# RK3399-AP register map
File version: 1
CPU: CA7 r0p1, little endian, MPU, FPU, I-cache, D-cache, VTOR, 4 interrupt priority bits, 0 interrupts
Registers are 32-bit, read-write, reset 0x0 unless marked. A register's access mark holds for its fields unless they carry their own. Offsets are from the block's base; [hi:lo] are bit positions; {n}, {i} and the like mark numbered series.

## PCIE
Base 0xF8000000
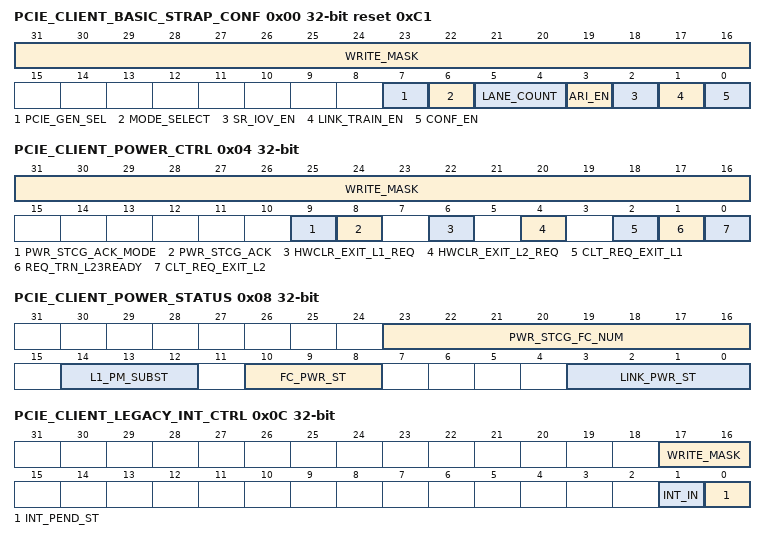
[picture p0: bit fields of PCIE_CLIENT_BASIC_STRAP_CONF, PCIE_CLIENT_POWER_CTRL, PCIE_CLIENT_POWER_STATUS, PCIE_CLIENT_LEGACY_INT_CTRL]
0x00 PCIE_CLIENT_BASIC_STRAP_CONF access per field reset 0xC1 — Basic strap configuration register
  [31:16] WRITE_MASK wo — Write mask bits For each served bit 1\'b0: write mask 1\'b1: write enable
  [7] PCIE_GEN_SEL rw — Generation support select 1\'b0: Gen1 mode 1\'b1: Gen2 mode This strap input selects the generation of the PCI Express protocol supported by the core. If Gen1 mode. The core advertises only Gen1 capability in this mode, and will always operate at Gen1 speed. If Gen2 mode. The core advertises Gen1 and Gen2 capabilities in this mode, but not Gen3. The link may operate at Gen1 or Gen2 speed.
  [6] MODE_SELECT rw — Controller operation mode select 1\'b0: Endpoint operation 1\'b1: Root Port operation
  [5:4] LANE_COUNT rw — lane count in configure the lane count supported 2’b11: reserved 2’b10: X4 2’b01: X2 2’b00: X1
  [3] ARI_EN rw — Alternate interpretation enable 1\'b0: legacy interpretation of the PCI Routing ID 1\'b1: alternate interpretation of the PCI Routing ID This input is strapped to 0 for legacy interpretation of the PCI Routing ID (8-bit Bus + 5-bit Device + 3- bit Function). A 1 at this input enables the alternate interpretation (8-bit Bus + 8-bit Function).
  [2] SR_IOV_EN rw — Single root I/O virtualization feature enable 1\'b0: disable SR-IOV feature 1\'b1: enable SR-IOV feature In a core supporting the Single Root I/O Virtualization feature, this strap input must be tied high to enable the SR-IOV feature. The ari_en input must also be strapped high to enable the SR- IOV feature.
  [1] LINK_TRAIN_EN rw — Link training enable 1\'b0: Quite state 1\'b1: enable link training This input must be set to 1 to enable the LTSSM to bring up the link. Setting it to 0 forces the LTSSM to stay in the Detect Quiet state.
  [0] CONF_EN rw — Config enable 1\'b0: disable 1\'b1: enable When this input is set to 0 in the EP mode, the core will generate a CRS Completion in response to Configuration Requests. In systems where the core configuration registers are loaded from RAM on power-up, this prevents the core from responding to Configuration Requests before all the registers are loaded. This input can be strapped high when the power-on default values of the Configuration Registers do not need to be modified before Configuration Space enumeration.
0x04 PCIE_CLIENT_POWER_CTRL access per field — PCIe client power control configuration
  [31:16] WRITE_MASK wo — Write mask bits For each served bit 1\'b0: write mask 1\'b1: write enable
  [9] PWR_STCG_ACK_MODE rw — Power state change ack mode select 1\'b0: select power state change ack source from bit pwr_stcg_ack 1\'b1: select power state change ack source from constant, it always keeps high.
  [8] PWR_STCG_ACK wo — Power state change ack 1\'b0: keep 0 1\'b1: write 1 to generate one high pulse ack to controller The client must assert this input to the core for one cycle in response to the assertion of power state change interrupt, when it is ready to transition to the low-power state requested by the configuration write request. The client may permanently maintain this input high if it does not need to delay the return of the completions for the configuration write transactions causing power-state changes.
  [6] HWCLR_EXIT_L1_REQ rw — Hardware clear exit L1 request 1\'b0: software polling and write clear mode 1\'b1: hardware polling and auto-clear mode
  [4] HWCLR_EXIT_L2_REQ rw — Hardware clear exit L2 request 1\'b0: software polling and write clear mode 1\'b1: hardware polling and auto-clear mode
  [2] CLT_REQ_EXIT_L1 rw — Client request exit L1 power state 1\'b0: keep 1\'b1: request to exit the L1.1 or L1.2.Idle substate Client request to exit the L1.1 or L1.2.Idle substate. When the core clock is turned off, the client must activate this input to request the L1 PM substate state machine to de-assert CLKREQ_OUT and transition the link out of L1. If the core clock is not turned off in the L1.1 and L1.2 substates, this input can be permanently kept low.
  [1] REQ_TRN_L23READY rw — Request transition to L23_Ready state 1\'b0: keep 1\'b1: transition the power management state of the core to L23_READY When the core is configured as Endpoint, the client may assert this input to transition the power management state of the core to L23_READY (see Chapter 5 of PCI Express Specifications for a detailed description of power management). This is done after the PCI Functions in the core have been placed in the D3 state and after the client has acknowledged the PME_Turn_Off message from the Root Port. Asserting this input causes the link to transition to the L2 state, and requires a power-on reset to resume operation. This input can be hardwired to 0 if the link is not required to transition to L2. This input is not used in the Root Port mode.
  [0] CLT_REQ_EXIT_L2 rw — Client request exit L2 power state 1\'b0: keep 1\'b1: Exit from L2_IDLE This input can be asserted by the client only in the short interval of time after the link enters L2 and before the system is powered OFF. While the power and clocks are still ON, the client can assert this input to initiate an exit from L2_IDLE->DETECT.
0x08 PCIE_CLIENT_POWER_STATUS ro — PCIe power management status
  [23:16] PWR_STCG_FC_NUM — Power state change function number Function number of the function for which a power state change occurred.
  [14:12] L1_PM_SUBST — L1 power management substate This output provides the current state of the L1 PM substates state machine. This output is in the PM_CLK clock domain. Its encodings are: 3\'b000 = LTSSM not in L1 state 3\'b001 = L1.0 substate 3\'b010 = L1.1 substate 3\'b011 = Reserved 3\'b100 = L1.2.Entry substate 3\'b101 = L1.2.Idle substate 3\'b110 = L1.2.Exit substate 3\'b111 = Reserved
  [10:8] FC_PWR_ST — Function power state These outputs provide the current power state of the Physical Functions. Bits [2:0] capture the power state of Function 0 The possible power states are: 3\'b000: D0_uninitialized 3\'b001: D0_active 3\'b010: D1 3\'b100: D3_hot
  [3:0] LINK_PWR_ST — Link power state Current power state of the PCIe link: 4\'b0001 = L0 4\'b0010 = L0s 4\'b0100 = L1 4\'b1000 = L2
0x0C PCIE_CLIENT_LEGACY_INT_CTRL access per field — Legacy interrupt control
  [17:16] WRITE_MASK wo — Write mask For each served bit 1\'b0: write mask 1\'b1: write enable
  [1] INT_IN rw — Legacy interrupt input 1\'b0: de-assert 1\'b1: assert When the core is configured as EP, this input is used by the client application to signal an interrupt from any of its PCI Functions to the RC using the Legacy PCI Express Interrupt Delivery mechanism of PCI Express. This input corresponds to INTA of the PCI bus. Asserting this signal causes the core to send out an Assert_INTx message, and de-asserting this signal causes the core to transmit a Deassert_INTx message.
  [0] INT_PEND_ST rw — Legacy interrupt pending status 1\'b0: normal 1\'b1: pending When using legacy interrupts, this input is used to indicate the interrupt pending status of the Physical Functions. The input i must be set when an interrupt is pending in Function i.
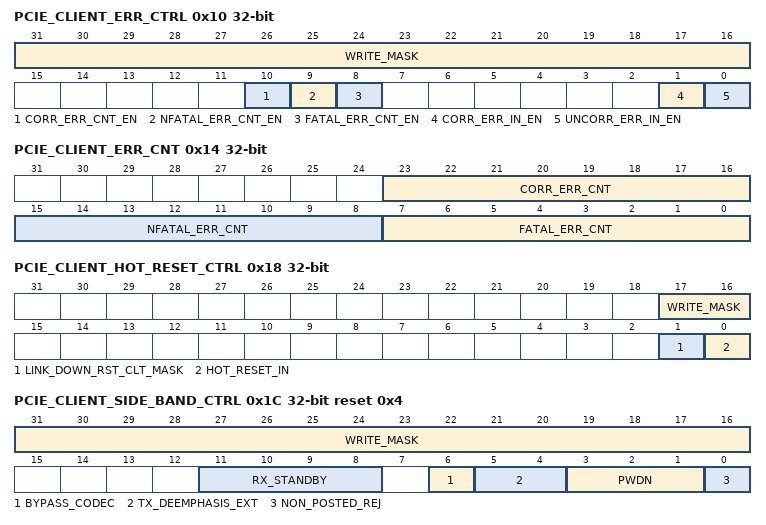
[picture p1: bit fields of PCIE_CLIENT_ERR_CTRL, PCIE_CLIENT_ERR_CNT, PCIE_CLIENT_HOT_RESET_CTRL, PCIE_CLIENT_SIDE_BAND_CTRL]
0x10 PCIE_CLIENT_ERR_CTRL access per field — Error control register
  [31:16] WRITE_MASK wo — Write mask For each served bit 1\'b0: write mask 1\'b1: write enable
  [10] CORR_ERR_CNT_EN rw — Enable correctable error counter 1\'b0: disable counter 1\'b1: enable counter
  [9] NFATAL_ERR_CNT_EN rw — Enable non-fatal error counter 1\'b0: disable counter 1\'b1: enable counter
  [8] FATAL_ERR_CNT_EN rw — Enable fatal error counter 1\'b0: disable counter 1\'b1: enable counter
  [1] CORR_ERR_IN_EN wo — Assert a correctable error input to core 1\'b0: no error 1\'b1: write one to generate one pulse The client may activate this input for one cycle to indicate a correctable error detected within the client logic that needs to be reported as an internal error through the PCI Express Advanced Error Reporting mechanism. In response, the core sets the Corrected Internal Error Status bit in the AER Correctable Error Status Register of all enabled Functions, and in EP mode also sends an error message if enabled to do so. This error is not considered Function-specific.
  [0] UNCORR_ERR_IN_EN wo — Assert an uncorrectable error input to core 1\'b0: no error 1\'b1: write one to generate one pulse The client may activate this input for one cycle to indicate an uncorrectable error detected within the client logic that needs to be reported as an internal error through the PCI Express Advanced Error Reporting mechanism. In response, the core sets the Uncorrectable Internal Error Status bit in the AER Uncorrectable Error Status Register of all enabled Functions, and in EP mode also sends an error message if enabled to do so. This error is not considered Function-specific.
0x14 PCIE_CLIENT_ERR_CNT — Error counter
  [23:16] CORR_ERR_CNT write-1-clears — Correctable error counter Correctable error counter, write all one(8\'hff) clear the counter.
  [15:8] NFATAL_ERR_CNT write-1-clears — Non-fatal error counter Non-fatal error counter, write all one(8\'hff) clear the counter.
  [7:0] FATAL_ERR_CNT write-1-clears — Fatal error counter Fatal error counter, write all one(8\'hff) clear the counter.
0x18 PCIE_CLIENT_HOT_RESET_CTRL access per field — Hot reset control
  [17:16] WRITE_MASK wo — Write mask For each served bit 1\'b0: write mask 1\'b1: write enable
  [1] LINK_DOWN_RST_CLT_MASK rw — Mask link down reset client logic 1\'b0: disable link down reset client logic 1\'b1: enable link down reset client logic
  [0] HOT_RESET_IN rw — Assert hot reset to remote device 0: de-assert 1: assert When this input is asserted in the RC mode, the core initiates a Hot Reset sequence on the PCIe link. This signal should be driven synchronous to the CORE_CLK domain. The controller will keep the PCIe link in hot reset till the time this signal is driven asserted. When de-asserted, controller will bring the PCIe link out of hot reset and initiate link training
0x1C PCIE_CLIENT_SIDE_BAND_CTRL access per field reset 0x4 — Side band control configuration
  [31:16] WRITE_MASK wo — Write mask For each served bit 1\'b0: write mask 1\'b1: write enable
  [11:8] RX_STANDBY rw — PCIe phy receiver control Controls whether the PHY RX is active when the PHY is in P0 or P0s states. 1\'b0: Active 1\'b1: Standby In other modes not mentioned above, this signal is ignored. One bit for each lane.
  [6] BYPASS_CODEC rw — PIPE bypass codec configuration Controls whether the PHY performs 8b/10b encode and decode: 1\'b0: 8b/10b encode/decode performed normally 1\'b1: 8b/10b encode/decode bypassed Data bus width is 20 bits, TxDataK and RxDataK interfaces are not used, if encode/decode bypassed, and WIDTH_I shall be set high.
  [5:4] TX_DEEMPHASIS_EXT rw — PIPE phy extended de-emphasis configuration, it combine with the standard pipe de-emphasis.
  [3:1] PWDN ro — Power state of the phy Power up or down the transceiver. 3\'b000: P0, normal operation 3\'b001: P0s, power saving state 3\'b010: P1, lower power state 3\'b011: P2, lowest power state, PLL not powered 3\'b111: L1SS.2, common mode off others : L1SS.1, common mode on
  [0] NON_POSTED_REJ rw — PCIe target non posted reject 1\'b0: normal operation 1\'b1: reject non posted request This is a single bit input signal which can be asserted by client logic when it cannot service a non-posted request. The core will not present any non-posted requests that it receives from the PCIe Link. It will hold them in the PNP FIFO RAM till the signal is de-asserted. If a non-posted TLP has already been queued from the PNP FIFO and this signal is asserted, the core will place it on the AXI bridge. The client logic must accept the non-posted TLP. The in-flight non-posted TLPs in the core from the PNP FIFO cannot be stopped. However, non-posted TLPs that are in the PNP FIFO RAM when this signal is asserted or come in after the signal is asserted will not be forwarded to the AXI interface. The client must assert this signal when it still can process two or three non-posted TLPs. This will allow posted TLPs to go past non-posted TLPs at the AXI master write interface due to client not being able to service non- posted TLPs.
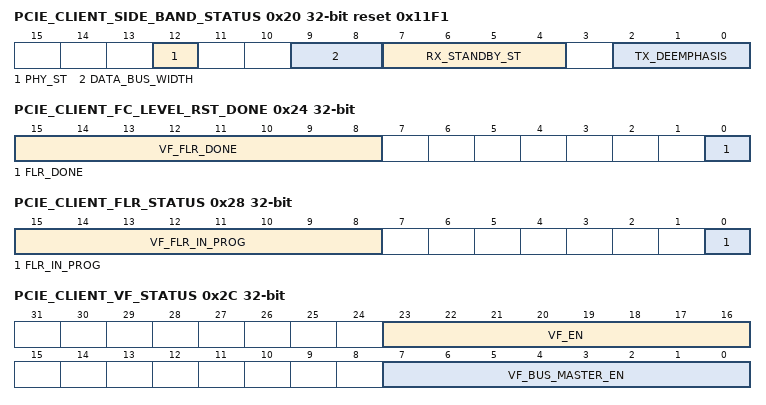
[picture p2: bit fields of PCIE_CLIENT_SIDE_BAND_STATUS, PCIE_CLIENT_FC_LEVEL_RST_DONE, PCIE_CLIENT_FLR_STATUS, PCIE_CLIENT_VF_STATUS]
0x20 PCIE_CLIENT_SIDE_BAND_STATUS ro reset 0x11F1 — Side band status
  [12] PHY_ST — PIPE phy status It indicates completion of several PHY functions including power management state transition and receiver detection. When this signal transitions during entry and exit from any PHY state where PCLK is not provided, then the signaling is asynchronous. When phy power up, "0" state can indicates pll locked
  [9:8] DATA_BUS_WIDTH — PIPE interface data bus width Reports the width of the data bus that the PHY is configured for: 1\'b0: 32-bit mode 1\'b1: 16-bit mode 0thers: reserved When bypass_codec is high, the interface is 20-bit and these two bits report a value of 2\'b01.
  [7:4] RX_STANDBY_ST — RX standby status Indicates PHY\'s RxStandby state 1\'b0: Active 1\'b1: Standby Always high during P1/P2/L1SS state.
  [2:0] TX_DEEMPHASIS — PIPE phy de-emphasis status Transmitter de-emphasis selection, it combined by tx_deemphasis_ext,tx_deemphasis. 3\'b000: -6dB de-emphasis 3\'b001: -3.5dB de-emphasis 3\'b010: 0dB de-emphasis 3\'b011: -5.5dB de-emphasis 3\'b100: -6.5dB de-emphasis 3\'b101: -4dB de-emphasis 3\'b110: -1dB de-emphasis 3\'b111: -3dB de-emphasis
0x24 PCIE_CLIENT_FC_LEVEL_RST_DONE wo — Generate function level reset done pulse
  [15:8] VF_FLR_DONE — Virtual function level reset done pulse generate The client must assert bit i of this bus when it has completed the reset operation of Virtual Function i. This causes the core to de- assert FLR_IN_PROGRESS for VF i and to re-enable configuration accesses to the VF. Write one to generate one high pulse.
  [0] FLR_DONE — Physical function level reset done pulse generate The client must assert bit i of this bus when it has completed the reset operation of Function i. This causes the core to de-assert FLR_IN_PROGRESS for Function i and to re-enable configuration accesses to the Function. Write one to generate one high pulse.
0x28 PCIE_CLIENT_FLR_STATUS ro — Function level reset status
  [15:8] VF_FLR_IN_PROG — Virtual function level reset in progress The core asserts bit i of this bus when the host initiates a reset of Virtual Function i though its FLR bit in the configuration space. The core continues to maintain the output high until the client sets the FLR_DONE input for the corresponding VF to indicate the completion of the reset operation. One bit for each function 1\'b0: normal 1\'b1: function level reset in progress
  [0] FLR_IN_PROG — Function level reset in progress The core asserts bit i of this bus when the host initiates a reset of Function i though its FLR bit in the configuration space. The core continues to maintain the output high until the client sets the FLR_DONE input for the corresponding Function to indicate the completion of the reset operation. 1\'b0: normal 1\'b1: function level reset in progress
0x2C PCIE_CLIENT_VF_STATUS ro — Virtual function status
  [23:16] VF_EN — Virtual function enable The core sets bit i of this bus when the host has configured the corresponding Virtual Function i. Client logic must check the state of this bit before initiating any request from the VF. 1\'b0: disable 1\'b1: enable One bit for each function
  [7:0] VF_BUS_MASTER_EN — Virtual function bus master enable Bit i of this bus reflects the setting of the Bus Master Enable bit of the PCI Command Register of Virtual Function i. Client logic must check the state of this bit before initiating any memory read or write transactions from the VF. 1\'b0: disable 1\'b1: enable One bit for each function
0x30 PCIE_CLIENT_VF_PWR_STATUS ro — Virtual function power status
  [23:0] VF_PWR_ST — Virtual function power status These outputs provide the current power state of the Virtual Functions. Bits [2:0] capture the power state of Virtual Function 0 , bits [5:3] capture that of Virtual Function 1, and so on. The possible power states are: 3\'b000: D0_uninitialized 3\'b001: D0_active 3\'b010: D1 3\'b100: D3_hot
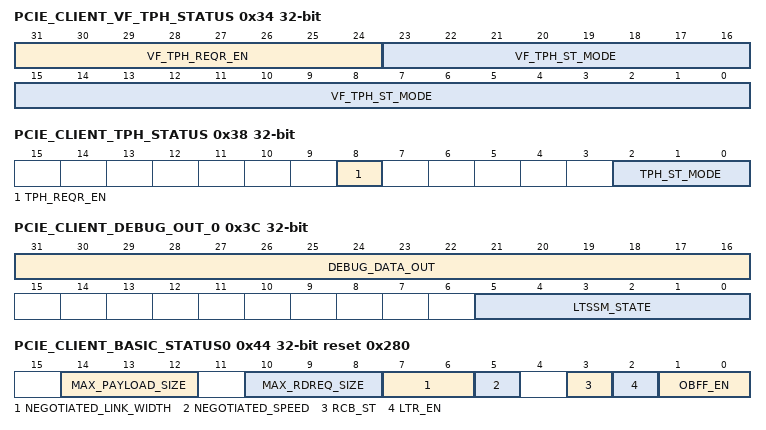
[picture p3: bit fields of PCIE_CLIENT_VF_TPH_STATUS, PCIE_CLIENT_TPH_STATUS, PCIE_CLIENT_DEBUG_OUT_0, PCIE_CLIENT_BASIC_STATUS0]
0x34 PCIE_CLIENT_VF_TPH_STATUS ro — Virtual function TPH status
  [31:24] VF_TPH_REQR_EN — Virtual function TPH requester enable Each of the 16 bits of this output is driven the TPH Requester Enable bit [8] of the TPH Requester Control Register in the TPH Requester Capability Structure of the corresponding Virtual Function. These bits are active only in the Endpoint mode when SR-IOV is enabled. They indicate whether the software has enabled the device to generate requests with TPH Hints from the associated Virtual Function.
  [23:0] VF_TPH_ST_MODE — Virtual function TPH steering tag mode Bits [2:0] of this output reflect the setting of the ST Mode Select bits in the TPH Requester Control Register of Virtual Function 0. Bits [5:3] reflect the setting of the same register field of VF 1, and so on. These bits are active only in the Endpoint mode. They indicate the allowed modes for generation of TPH Hints by the corresponding VF.
0x38 PCIE_CLIENT_TPH_STATUS ro — Physical TPH status
  [8] TPH_REQR_EN — Physical function TPH requester enable Bit 0 of this output is drives the TPH Requester Enable bit [8] of the TPH Requester Control Register in the TPH Requester Capability Structure of the Physical Function 0. These bits are active only in the Endpoint mode. They indicate whether the software has enabled the device to generate requests with TPH Hints from the associated Physical Function.
  [2:0] TPH_ST_MODE — Physical function TPH steering tag mode Bits [2:0] of this output reflect the setting of the ST Mode Select bits in the TPH Requester Control Register of Physical Function 0. These bits are active only in the Endpoint mode. They indicate the allowed modes for generation of TPH Hints by the corresponding Physical Function.
0x3C PCIE_CLIENT_DEBUG_OUT_0 ro — Debug information 0
  [31:16] DEBUG_DATA_OUT — Output data from the debug bus 16-bit output data from the debug bus, described in Appendix A
  [5:0] LTSSM_STATE — Link training and status state Current state of the Link Training and Status State Machine within the core. The encodings of this output are described in Appendix B
0x40 PCIE_CLIENT_DEBUG_OUT_1 ro — Debug information 1
  [17:0] PERF_DATA_OUT — Performance data out Each of the bits of this vector is explained below: Bit[17]:Pulse appears when event happens,described in Appendix B
0x44 PCIE_CLIENT_BASIC_STATUS0 ro reset 0x280 — Basic status 0
  [14:12] MAX_PAYLOAD_SIZE — Max payload size The maximum payload size field programmed in the PCI Express Device Control Register. In multiple function cores, this output provides the minimum of the max-payload-size field in the Device Control Registers of all the enabled Physical Functions. The client logic must limit the size of Outgoing Completion payloads to this value. The 3-bit codes are the same as those defined in PCIe Specifications: 3\'b000 = 128 bytes 3\'b001 = 256 bytes 3\'b010 = 512 bytes 3\'b011 = 1024 bytes 3\'b100 = 2048 bytes 3\'b101 = 4096 bytes
  [10:8] MAX_RDREQ_SIZE — Max read request size The maximum request size field programmed in the PCI Express Device Control Register. In multi?Function cores, this output provides the minimum of the max-read-request field in the Device Control Registers of all the Physical Functions. The client logic must limit the size of outgoing read requests to this value. The 3-bit codes are the same as those defined in PCIe Specifications: 3\'b000 = 128 bytes 3\'b001 = 256 bytes 3\'b010 = 512 bytes 3\'b011 = 1024 bytes 3\'b100 = 2048 bytes 3\'b101 = 4096 bytes
  [7:6] NEGOTIATED_LINK_WIDTH — Negotiated link width Current link width are as follows: 2\'b10: x4 2\'b01: x2 2\'b00: x1 others: Reserved
  [5] NEGOTIATED_SPEED — Operation speed after negotiation Current operating speed of the link is as follows: 1\'b0: 2.5GT/s 1\'b1: 5GT/s
  [3] RCB_ST — Read completion boundary status Provides the setting of the Read Completion Boundary (RCB) bit in the Link Control Register of each Physical Function. In the Endpoint mode, bit 0 indicates the RCB for PF 0 and so on. In the RC mode, bit 0 indicates the RCB setting of the Link Control Register of the RC. For each bit, a value of 1\'b0: indicates an RCB of 64 bytes 1\'b1: indicates 128 bytes
  [2] LTR_EN — Latency tolerance reporting mechanism enable The state of this output reflects the setting of the LTR Mechanism Enable bit in the Device Control 2 Register of Physical Function 0. When the core is configured as an Endpoint, client logic uses this output to enable the generation of LTR messages. This output is not to be used when the core is configured as a Root Complex. 1\'b0: disable 1\'b1: enable
  [1:0] OBFF_EN — Optimized buffer flush and fill enable This output reflects the setting of the OBFF Enable field in the Device Control 2 Register 2\'b00: OBFF disabled, 2\'b01: OBFF enabled using message signaling, Variation A, 2\'b10: OBFF enabled using message signaling, Variation B, 2\'b11: OBFF enabled using WAKE# signaling.
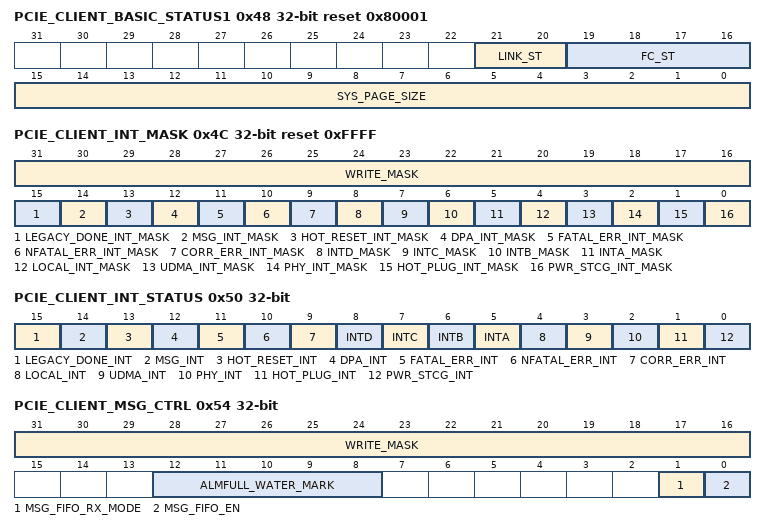
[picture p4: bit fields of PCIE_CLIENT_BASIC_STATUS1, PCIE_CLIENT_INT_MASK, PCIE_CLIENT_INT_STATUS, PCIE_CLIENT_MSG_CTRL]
0x48 PCIE_CLIENT_BASIC_STATUS1 ro reset 0x80001 — Basic status 1
  [21:20] LINK_ST — Link status Status of the PCI Express link. 2\'b00 = No receivers detected. 2\'b01 = Link training in progress. 2\'b10 = Link up , DL initialization in progress. 2\'b11 = Link up, DL initialization completed.
  [19:16] FC_ST — Function status These outputs indicate the states of the Command Register bits in the PCI configuration space of each Function. These outputs are used to enable requests and completions from the host logic. The assignment of bits is as follows: Bit 0: Function 0 IO Space Enable Bit 1: Function 0 Memory Space Enable Bit 2: Function 0 Bus Master Enable Bit 3: Function 0 INTx Disable and so on depending on the number of functions.
  [15:0] SYS_PAGE_SIZE — System page size These bits reflect the setting of the System Page Size Register in the SR IOV capability of each PF. Bits [15:0] reflect bits [15:0] of System Page Size register of PF0
0x4C PCIE_CLIENT_INT_MASK access per field reset 0xFFFF — Interrupt mask
  [31:16] WRITE_MASK wo — Write mask For each served bit 1\'b0: write mask 1\'b1: write enable
  [15] LEGACY_DONE_INT_MASK rw — Legacy interrupt send done interrupt mask 1\'b0: interrupt enable 1\'b1: interrupt mask
  [14] MSG_INT_MASK rw — Message receive done interrupt mask 1\'b0: interrupt enable 1\'b1: interrupt mask
  [13] HOT_RESET_INT_MASK rw — Hot reset interrupt mask 1\'b0: interrupt enable 1\'b1: interrupt mask
  [12] DPA_INT_MASK rw — DPA interrupt mask 1\'b0: interrupt enable 1\'b1: interrupt mask
  [11] FATAL_ERR_INT_MASK rw — Fatal error interrupt mask 1\'b0: interrupt enable 1\'b1: interrupt mask
  [10] NFATAL_ERR_INT_MASK rw — Non-fatal error interrupt mask 1\'b0: interrupt enable 1\'b1: interrupt mask
  [9] CORR_ERR_INT_MASK rw — Correctable error interrupt mask 1\'b0: interrupt enable 1\'b1: interrupt mask
  [8] INTD_MASK rw — INTD interrupt mask 1\'b0: interrupt enable 1\'b1: interrupt mask
  [7] INTC_MASK rw — INTC interrupt mask 1\'b0: interrupt enable 1\'b1: interrupt mask
  [6] INTB_MASK rw — INTB interrupt mask 1\'b0: interrupt enable 1\'b1: interrupt mask
  [5] INTA_MASK rw — INTA interrupt mask 1\'b0: interrupt enable 1\'b1: interrupt mask
  [4] LOCAL_INT_MASK rw — Local interrupt mask 1\'b0: interrupt enable 1\'b1: interrupt mask
  [3] UDMA_INT_MASK rw — uDMA interrupt mask 1\'b0: interrupt enable 1\'b1: interrupt mask
  [2] PHY_INT_MASK rw — Phy interrupt mask 1\'b0: interrupt enable 1\'b1: interrupt mask
  [1] HOT_PLUG_INT_MASK rw — Hot plug interrupt mask 1\'b0: interrupt enable 1\'b1: interrupt mask reserved
  [0] PWR_STCG_INT_MASK rw — Power state change interrupt mask 1\'b0: interrupt enable 1\'b1: interrupt mask
0x50 PCIE_CLIENT_INT_STATUS access per field — Interrupt status
  [15] LEGACY_DONE_INT rw write-1-clears — Legacy interrupt send done interrupt 1\'b0: no interrupt 1\'b1: interrupt A pulse on this output indicates that the core has sent an INTx Assert or Deassert message in response to a change in the state of one of the int_in
  [14] MSG_INT rw write-1-clears — Message receive done interrupt 1\'b0: no interrupt 1\'b1: interrupt When a message received done by Client message FIFO, an interrupt will generate
  [13] HOT_RESET_INT rw write-1-clears — Hot reset interrupt 1\'b0: no interrupt 1\'b1: interrupt When a hot reset send done interrupt generated in RC mode, it indicates that the Endpoint Device has also received the Hot Reset, and then the hot_reset_in can be de-assert
  [12] DPA_INT rw write-1-clears — DPA interrupt 1\'b0: no interrupt 1\'b1: interrupt The core generates an interrupt when a Configuration Write transaction writes into the Dynamic Power Allocation Control Register to modify the DPA power state of the device. A interrupt indicates such a DPA event for PF 0, and so on. The local software running on the End Point must read the DPA Control Register of the corresponding Function to determine the DPA substate requested by the host and set the power state of the device accordingly
  [11] FATAL_ERR_INT rw write-1-clears — Fatal error interrupt 1\'b0: no interrupt 1\'b1: interrupt In the EP mode, the core activates this output for one cycle when it has detected a fatal error and its reporting is not masked. In multi-Function cores, this is the logical OR of the fatal error status bits in the Device Status Registers of all Functions. In the RP mode, this output is activated on detection of a local fatal error, when its reporting is not masked. This signal also gets activated in response to an error message received from the link if Fatal Error Reporting is enabled in the Root Error Command register.
  [10] NFATAL_ERR_INT rw write-1-clears — Non-fatal error interrupt 1\'b0: no interrupt 1\'b1: interrupt In the EP mode, the core activates this output for one cycle when it has detected a non-fatal error and its reporting is not masked. In multi-Function cores, this is the logical OR of the non-fatal error status bits in the Device Status Registers of all Functions. In the RC mode, this output is activated on detection of a local fatal error, when its reporting is not masked. This signal also gets activated in response to an error message received from the link if Fatal Error Reporting is enabled in the Root Error Command register.
  [9] CORR_ERR_INT rw write-1-clears — Correctable error interrupt 1\'b0: no interrupt 1\'b1: interrupt In the EP mode, the core activates this output for one cycle when it has detected a correctable error and its reporting is not masked. In multi-Function cores, this is the logical OR of the correctable error status bits in the Device Status Registers of all Functions. In the RC mode, this output is activated on detection of a local correctable error, when its reporting is not masked. This signal also gets activated in response to an error message received from the link if Correctable Error Reporting is enabled in the Root Error Command register.
  [8] INTD ro — INTD interrupt 1\'b0: no interrupt 1\'b1: interrupt When the core is configured as RC, this interrupt emulate the PCI legacy interrupts INTD. The core asserts an interrupt output when it has received an Assert_INTD message from the link, and deasserts it when it receives a Deassert_INTD message.
  [7] INTC ro — INTC interrupt 1\'b0: no interrupt 1\'b1: interrupt When the core is configured as RC, this interrupt emulate the PCI legacy interrupts INTC. The core asserts an interrupt output when it has received an Assert_INTC message from the link, and deasserts it when it receives a Deassert_INTC message.
  [6] INTB ro — INTB interrupt 1\'b0: no interrupt 1\'b1: interrupt When the core is configured as RC, this interrupt emulate the PCI legacy interrupts INTB. The core asserts an interrupt output when it has received an Assert_INTB message from the link, and deasserts it when it receives a Deassert_INTB message.
  [5] INTA ro — INTA interrupt 1\'b0: no interrupt 1\'b1: interrupt When the core is configured as RC, this interrupt emulate the PCI legacy interrupts INTA. The core asserts an interrupt output when it has received an Assert_INTA message from the link, and deasserts it when it receives a Deassert_INTA message.
  [4] LOCAL_INT ro — Local interrupt 1\'b0: no interrupt 1\'b1: interrupt Local Error and Status Register Interrupt. This is a level interrupt till cleared by software Detail information refers to Local Error and Status Register description in PCIe Core register section "Local Management Registers"
  [3] UDMA_INT ro — uDMA interrupt 1\'b0: no interrupt 1\'b1: interrupt DMA Interrupt to the system processor. Will be asserted on a "DMA Done" or a "DMA Error" event
  [2] PHY_INT ro — Phy interrupt 1\'b0: no interrupt 1\'b1: interrupt This interrupt is used by the core in the RP mode to signal one of the following link training-related events: 1. The link bandwidth changed as a result of the change in the link width or operating speed and the change was initiated locally (not by the link partner), without the link going down. This interrupt is enabled by the Link Bandwidth Management Interrupt Enable bit in the Link Control Register. The status of this interrupt can be read from the Link Bandwidth Management Status bit of the Link Status Register. 2. The link bandwidth changed autonomously as a result of the change in the link width or operating speed and the change was initiated by the remote node. This interrupt is enabled by the Link Autonomous Bandwidth Interrupt Enable bit in the Link Control Register. The status of this interrupt can be read from the Link Autonomous Bandwidth Status bit of the Link Status Register. The phy interrupt is not active when the core is configured as an EndPoint.
  [1] HOT_PLUG_INT ro — Hot plug interrupt 1\'b0: no interrupt 1\'b1: interrupt Hot Plug Interrupt Output for Software Notification of Hot Plug events. Currently, this interrupt reserved
  [0] PWR_STCG_INT ro — Power state change interrupt 1\'b0: no interrupt 1\'b1: interrupt The core asserts this output when the power state of a Physical or Virtual Function is being changed to the D1 or D3 states by a write into its Power Management Control Register. The core maintains this output high until the client asserts the pwr_stcg_ack input to the core. While interrupt remains high, the core will not return completions for any pending configuration read or write transaction received by the core. The intent is to delay the completion for the configuration write transaction that caused the state change until the client is ready to transition to the low- power state. When interrupt is asserted, the Function number associated with the configuration write transaction is provided on the pwr_stcg_fc_num. When the client asserts pwr_stcg_ack, the new state of the Function that underwent the state change will be reflected on the fc_pwr_st (for PFs) or the vf_pwr_st (for VFs) outputs of the core.
0x54 PCIE_CLIENT_MSG_CTRL access per field — Message receive control register
  [31:16] WRITE_MASK wo — Write mask For each served bit 1\'b0: write mask 1\'b1: write enable
  [12:8] ALMFULL_WATER_MARK rw — Almost full water mark almost full water mark configuration
  [1] MSG_FIFO_RX_MODE rw — Message fifo receive mode select 1\'b0: partial mode 1\'b1: full mode
  [0] MSG_FIFO_EN rw — Message fifo receive enable 1\'b0: disable message receive 1\'b1: enable client message receive
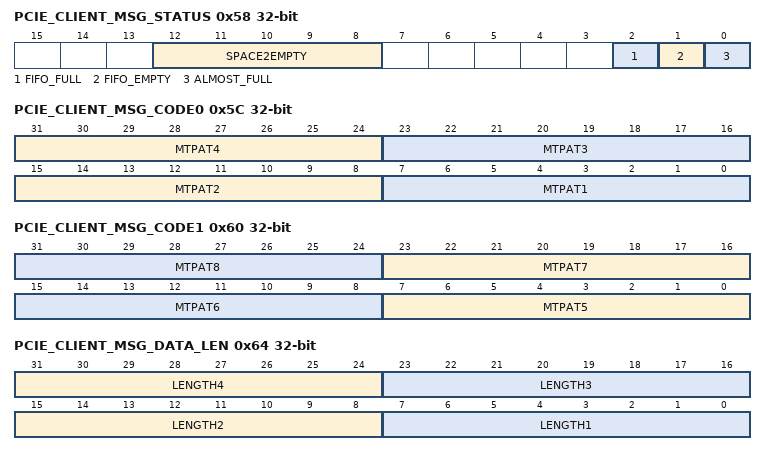
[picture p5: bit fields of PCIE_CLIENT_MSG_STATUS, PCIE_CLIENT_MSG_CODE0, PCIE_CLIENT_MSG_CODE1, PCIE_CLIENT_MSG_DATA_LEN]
0x58 PCIE_CLIENT_MSG_STATUS ro — Message control status
  [12:8] SPACE2EMPTY — Space to empty Data length before empty
  [2] FIFO_FULL — Message fifo full 1\'b0: non-full 1\'b1: fifo full
  [1] FIFO_EMPTY — Message fifo empty 1\'b0: non-full empty 1\'b1: fifo_empty
  [0] ALMOST_FULL — Message fifo almost full flag 1\'b0: non-almost full 1\'b1: almost full
0x5C PCIE_CLIENT_MSG_CODE0 — Message code 0
  [31:24] MTPAT4 — Match pattern 4 Pattern4
  [23:16] MTPAT3 — Match pattern 3 Pattern3
  [15:8] MTPAT2 — Match pattern 2 Pattern2
  [7:0] MTPAT1 — Match pattern 1 Pattern 1
0x60 PCIE_CLIENT_MSG_CODE1 — Message code 1
  [8n-33:8n-40] MTPAT{n} (n=5..8) — Match pattern {n} Pattern{n}
0x64 PCIE_CLIENT_MSG_DATA_LEN ro — Message data length
  [31:24] LENGTH4 read-clears — Length4 Length4, record the 4th recently received message length.
  [23:16] LENGTH3 read-clears — Length3 Length3, record the 3rd recently received message length.
  [15:8] LENGTH2 read-clears — Length2 Length2, record the 2nd recently received message length.
  [7:0] LENGTH1 read-clears — Length1 Length1, record the recently received message length.
0x100 PCIE_CLIENT_MSG_FIFO_RD_DATA ro — Message fifo read data
  [31:0] RD_DATA — Message fifo read data Message fifo read data
0x200 PCIE_CLIENT_CONF_NU0 access not given — Configuration no used
0x204 PCIE_CLIENT_CONF_NU1 access not given — Configuration no used
